# SN32F760 register map
Vendor: SONiX Technology Co., Ltd.; Series: SN32F760; File version: 2.0
ARM 32-bit Cortex-M0 Microcontroller based device, CPU clock up to 50MHz, etc.
CPU: CM0 r0p0, little endian, no MPU, no FPU, 2 interrupt priority bits
Registers are 32-bit, read-write, reset 0x0 unless marked. A register's access mark holds for its fields unless they carry their own. Offsets are from the block's base; lines under a group give offsets from that group; [hi:lo] are bit positions; {n}, {i} and the like mark numbered series; 'fields as' and 'values as' point back to an identical list; <NAME> marks a mode.

## Memory map
0x1FFF2C08 SN_UC size 0x2000 — UC Registers
0x40000000 SN_CT16B0 size 0x2000 — 16-bit Timer 0 with Capture function
0x40002000 SN_CT16B1 size 0x2000
0x40004000 SN_CT16B2 size 0x2000
0x40006000 SN_CT32B0 size 0x2000 — 32-bit Timer 0 with Capture function
0x40008000 SN_CT32B1 size 0x2000
0x4000A000 SN_CT32B2 size 0x2000
0x40010000 SN_WDT size 0x2000 — Watchdog Timer
0x40012000 SN_RTC size 0x2000 — Real-time Clock
0x40016000 SN_USART0 size 0x2000 — USART0
0x40018000 SN_I2C0 size 0x2000 — I2C0
0x4001A000 SN_I2S size 0x2000 — I2S
0x4001C000 SN_SSP0 size 0x2000 — SSP0
0x40026000 SN_ADC size 0x2000 — ADC
0x40032000 SN_PMU size 0x2000 — Power Management Unit
0x40034000 SN_LCD size 0x2000 — 4 x 32 LCD Driver
0x40042000 SN_PFPA size 0x2000 — Peripheral Function Pin Assignment
0x40044000 SN_GPIO0 size 0x2000 — General Purpose I/O
0x40046000 SN_GPIO1 size 0x2000
0x40048000 SN_GPIO2 size 0x2000 — General Purpose I/O
0x4004A000 SN_GPIO3 size 0x2000
0x40056000 SN_USART1 size 0x2000
0x40058000 SN_SSP1 size 0x2000
0x4005A000 SN_I2C1 size 0x2000
0x4005E000 SN_SYS1 size 0x2000 — System Control Registers
0x40060000 SN_SYS0 size 0x2000 — System Control Registers
0x40062000 SN_FLASH size 0x2000 — FLASH Memory Control Registers

## Interrupts
0 NDT (SN_SYS0)
2 LCD (SN_LCD)
3 I2S (SN_I2S)
6 SSP0 (SN_SSP0)
7 SSP1 (SN_SSP1)
10 I2C0 (SN_I2C0)
11 I2C1 (SN_I2C1)
13 USART0 (SN_USART0)
14 USART1 (SN_USART1)
15 CT16B0 (SN_CT16B0)
16 CT16B1 (SN_CT16B1)
17 CT16B2 (SN_CT16B2)
19 CT32B0 (SN_CT32B0)
20 CT32B1 (SN_CT32B1)
21 CT32B2 (SN_CT32B2)
23 RTC (SN_RTC)
24 ADC (SN_ADC)
25 WDT (SN_WDT)
26 LVD (SN_SYS0)
28 P3 (SN_GPIO3)
29 P2 (SN_GPIO2)
30 P1 (SN_GPIO1)
31 P0 (SN_GPIO0)

## SN_WDT — Watchdog Timer
Base 0x40010000
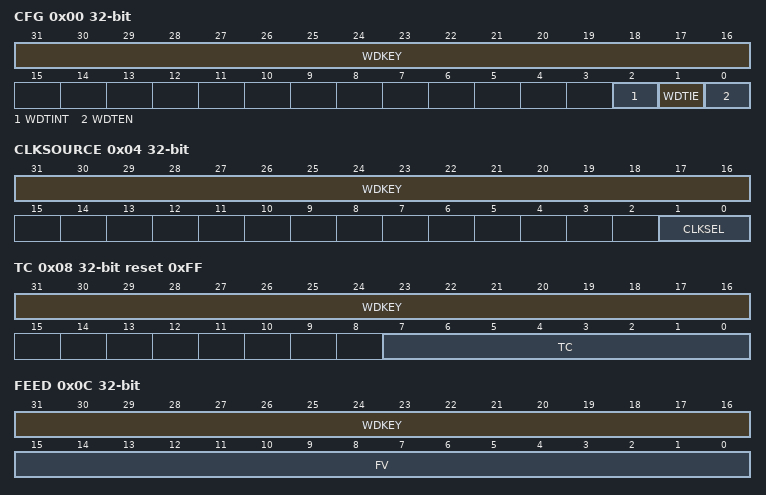
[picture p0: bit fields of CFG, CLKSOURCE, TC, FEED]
0x00 CFG — Offset:0x00 WDT Configuration Register
  [31:16] WDKEY wo — WDT register key
  [2] WDTINT — WDT interrupt flag
    0=No (No WDT time-out); 1=WDT time-out (WDT interrupt is triggered if WDTIE=1)
  [1] WDTIE — WDT interrupt enable
    0=Disable (WDT reset when WDT time-out); 1=Enable WDT interrupt
  [0] WDTEN — WDT enable
    0=Disable WDT; 1=Enable WDT
0x04 CLKSOURCE — Offset:0x04 WDT Clock Source Register
  [31:16] WDKEY wo — WDT register key
  [1:0] CLKSEL — WDT clock source
    0=IHRC (IHRC is WDT clock source); 1=HCLK (HCLK is WDT clock source); 2=ILRC (ILRC is WDT clock source); 3=ELS XTAL (ELS Xtal is WDT clock source)
0x08 TC reset 0xFF — Offset:0x08 WDT Timer Constant Register
  [31:16] WDKEY wo — WDT register key
  [7:0] TC — Watchdog timer constant reload value
0x0C FEED wo — Offset:0x0C WDT Feed Register
  [31:16] WDKEY — WDT register key
  [15:0] FV — Watchdog feed value

## SN_RTC — Real-time Clock
Base 0x40012000
0x00 CTRL — Offset:0x00 RTC Control Register
  [0] RTCEN — RTC enable
    0=Disable RTC; 1=Enable RTC
0x04 CLKS — Offset:0x04 RTC Clock Source Register
  [1:0] CLKSEL — RTC clock source
    0=ILRC (ILRC is RTC clock source); 1=ELS XTAL (ELS Xtal is RTC clock source); 3=EHS XTAL clock/128 (EHS Xtal/128 is RTC clock source)
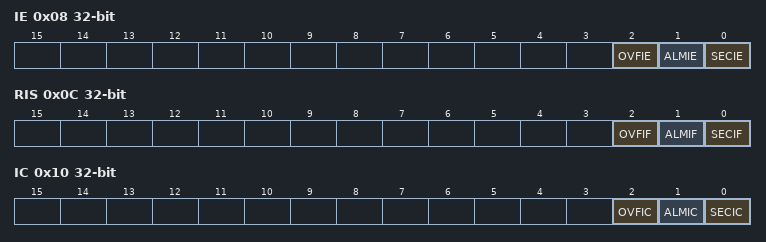
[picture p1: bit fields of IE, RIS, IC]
0x08 IE — Offset:0x08 RTC Interrupt Enable Register
  [2] OVFIE — Overflow interrupt enable
    0=Disable overflow interrupt; 1=Enable overflow interrupt
  [1] ALMIE — Alarm interrupt enable
    0=Disable alarm interrupt; 1=Enable alarm interrupt
  [0] SECIE — Second interrupt enable
    0=Disable second interrupt; 1=Enable second interrupt
0x0C RIS ro — Offset:0x0C RTC Raw Interrupt Status Register
  [2] OVFIF — Overflow interrupt flag
    0=No (No overflow interrupt); 1=Met overflow interrupt requirements (Overflow interrupt is triggered when OVFIE=1)
  [1] ALMIF — Alarm interrupt flag
    0=No (No alarm interrupt); 1=Met alarm interrupt requirements (Alarm interrupt is triggered when ALMIE=1)
  [0] SECIF — Second interrupt flag
    0=No (No second interrupt); 1=Met second interrupt requirements (Second interrupt is triggered when SECIE=1)
0x10 IC wo — Offset:0x10 RTC Interrupt Clear Register
  [2] OVFIC — Overflow interrupt flag clear
    0=No effect; 1=Clear overflow interrupt flag
  [1] ALMIC — Alarm interrupt flag clear
    0=No effect; 1=Clear alarm interrupt flag
  [0] SECIC — Second interrupt flag clear
    0=No effect; 1=Clear second interrupt flag
0x14 SECCNTV reset 0x8000 (reset mask 0xFFFFF) — Offset:0x14 RTC Second Counter Reload Value Register
0x18 SECCNT ro — Offset:0x18 RTC Second Counter Register
0x1C ALMCNTV reset 0xFFFFFFFF — Offset:0x1C RTC Alarm Counter Reload Value Register
0x20 ALMCNT ro — Offset:0x20 RTC Alarm Counter Register

## Licence text in the file
ARM Limited (ARM) is supplying this software for use with Cortex-M processor based microcontroller, but can be equally used for other suitable processor architectures. This file can be freely distributed. Modifications to this file shall be clearly marked. . THIS SOFTWARE IS PROVIDED "AS IS". NO WARRANTIES, WHETHER EXPRESS, IMPLIED. OR STATUTORY, INCLUDING, BUT NOT LIMITED TO, IMPLIED WARRANTIES OF. MERCHANTABILITY AND FITNESS FOR A PARTICULAR PURPOSE APPLY TO THIS SOFTWARE. ARM SHALL NOT, IN ANY CIRCUMSTANCES, BE LIABLE FOR SPECIAL, INCIDENTAL, OR. CONSEQUENTIAL DAMAGES, FOR ANY REASON WHATSOEVER.

## Notices in the file
Copyright (C) 2019 ARM Limited. All rights reserved.
